# WB32F10x register map
File version: 1.2
CPU: CM3 r2p0, little endian, MPU, no FPU, 4 interrupt priority bits
Registers are 32-bit, read-write, reset 0x0 unless marked. A register's access mark holds for its fields unless they carry their own. Offsets are from the block's base; [hi:lo] are bit positions; {n}, {i} and the like mark numbered series.

## CRC — Cyclic Redundancy Check
Base 0x40014800
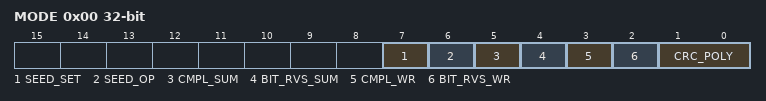
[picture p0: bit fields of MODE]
0x00 MODE — CRC mode register
  [7] SEED_SET — Load seed to CRC generator
  [6] SEED_OP — CRC seed option set
  [5] CMPL_SUM — Select one's complement for CRC_SUM
  [4] BIT_RVS_SUM — Select bit order revers for CRC_SUM
  [3] CMPL_WR — Select one's complement for CRC_WR_DATA
  [2] BIT_RVS_WR — Select bit order for CRC_WR_DATA
  [1:0] CRC_POLY — Select CRC polynomial field
0x04 SEED reset 0xFFFF — CRC seed register
  [31:0] SEED — CRC seed value
0x08 SUM ro reset 0xFFFF — CRC checksum register
  [31:0] SUM — CRC checksum
0x08 WDATA wo reset not defined — CRC data register
  [31:0] WDATA — CRC data

## RNG — Random Number Generator
Base 0x4000B800
0x00 RAND ro — Random number generator register
  [7:0] RAND — Generated 8-bit random number
0x04 STOP — RNG STOP register
  [0] STOP — RNG STOP control

## PWR — Power control
Base 0x40010000
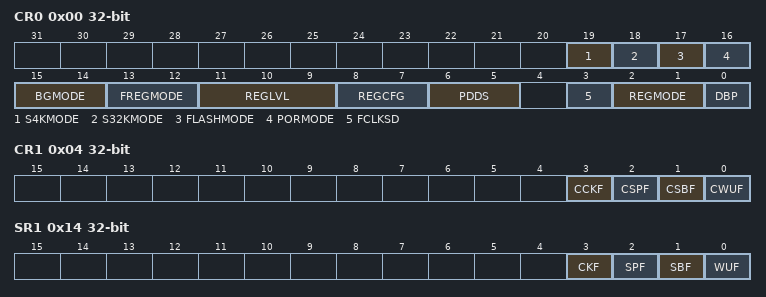
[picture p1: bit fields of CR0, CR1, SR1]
0x00 CR0 — Power control register 0
  [19] S4KMODE — Configure the state of 4K SRAM when it enters stop mode
  [18] S32KMODE — Configure the state of 32K SRAM when it enters stop mode
  [17] FLASHMODE — Configure the state of the flash memory when it enters stop mode
  [16] PORMODE — Configure the status of the POR BG when it enters stop mode
  [15:14] BGMODE — Configure the status of the bandgap when it enters the stop mode
  [13:12] FREGMODE — Configure the state of the flash regulator when it enters stop mode
  [11:9] REGLVL — Configure the step value of the voltage regulator
  [8:7] REGCFG — Configure the voltage change direction of the voltage regulator
  [6:5] PDDS — Configure the working state of the device when the Cortex ® -M3 enters deep sleep mode
  [3] FCLKSD — Reduce the frequency of Cortex ® -M3 FCLK
  [2:1] REGMODE — Configure the state of the voltage regulator when it enters stop mode
  [0] DBP — Disable the write protection for backup domain registers
0x04 CR1 wo — Control register 1
  [3] CCKF — Clear CKF flag bit
  [2] CSPF — Clear SPF flag bit
  [1] CSBF — Clear SBF flag bit
  [0] CWUF — Clear WUF flag bit
0x08 CR2 — Control register 2
  [0] EWUP — Enable WKUP pin
0x10 SR0 ro — Status register 0
  [0] PVD0 — PVD output
0x14 SR1 ro — Status register 1
  [3] CKF — CKF Flag
  [2] SPF — Stop flag
  [1] SBF — Standby flag
  [0] WUF — Wakeup flag
0x18 GPREG0 — General purpose register 0
0x1C GPREG1 — General purpose register 1
0x20 CFGR reset 0x3BE — Configuration register
  [12:0] LPCFG — Configure the time to enter and exit low power mode
0x28 ANAKEY1 wo — Analog enable register 1
0x2C ANAKEY2 wo — Analog enable register 2

## BKP — Backup registers
Base 0x40015C00
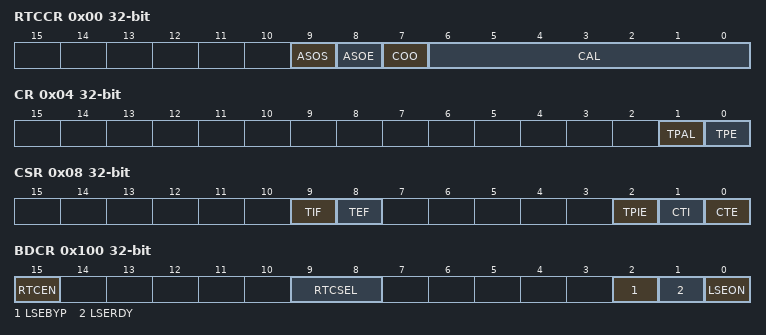
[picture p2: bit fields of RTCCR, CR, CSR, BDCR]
0x00 RTCCR — RTC signal output control register
  [9] ASOS — RTC output selection
  [8] ASOE — RTC alarm or second signal output enable
  [7] COO — RTC clock calibration output enable
  [6:0] CAL — RTC clock calibration value
0x04 CR — Tamper pin control register
  [1] TPAL — TAMPER pin active level
  [0] TPE — TAMPER detection enable
0x08 CSR — Tamper control and status register
  [9] TIF — Tamper interrupt flag
  [8] TEF — Tamper event flag
  [2] TPIE — Tamper interrupt enable
  [1] CTI — Tamper interrupt reset
  [0] CTE — Tamper event reset
{0xC+4i} DR{i} (i=1..21) — Backup data {i} register
  [31:0] DATA — Backup data
0x100 BDCR — Backup domain control register
  [15] RTCEN — RTC clock enable control, software set or clear this bit
  [9:8] RTCSEL — RTC clock source selection
  [2] LSEBYP — External Low-speed oscillator bypass
  [1] LSERDY — External low-speed oscillator ready
  [0] LSEON — External low-speed oscillator enable Set and cleared by software

## AFIO — AFIO registers
Base 0x40001400
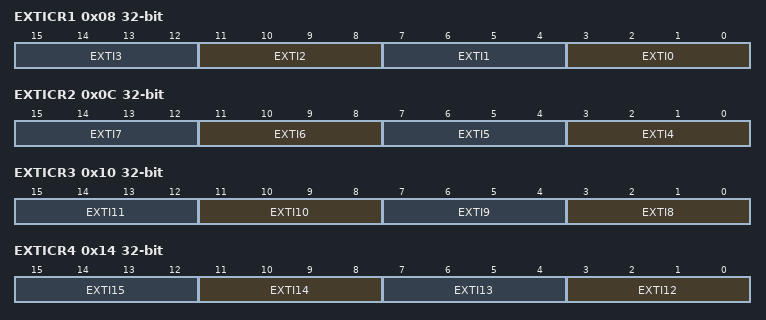
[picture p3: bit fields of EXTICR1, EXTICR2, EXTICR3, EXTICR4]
0x08 EXTICR1 — External interrupt configuration register 1
  [4n+3:4n] EXTI{n} (n=0..3) — EXTI x configuration {n}
0x0C EXTICR2 — External interrupt configuration register 2
  [4n-13:4n-16] EXTI{n} (n=4..7) — EXTI x configuration {n}
0x10 EXTICR3 — External interrupt configuration register 3
  [4n-29:4n-32] EXTI{n} (n=8..11) — EXTI x configuration {n}
0x14 EXTICR4 — External interrupt configuration register 4
  [4n-45:4n-48] EXTI{n} (n=12..15) — EXTI x configuration {n}
